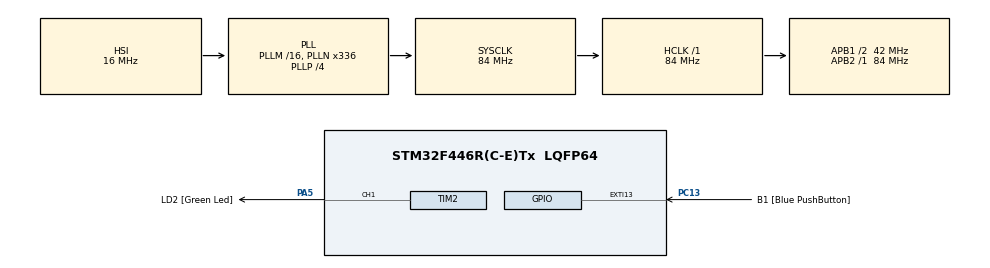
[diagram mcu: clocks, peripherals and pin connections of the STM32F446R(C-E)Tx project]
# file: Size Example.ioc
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Mcu.Family=STM32F4
Mcu.Name=STM32F446R(C-E)Tx
Mcu.Package=LQFP64
NVIC.PriorityGroup=NVIC_PRIORITYGROUP_0
PA13.GPIO_Label=TMS
PA13.Signal=SYS_JTMS-SWDIO
PA14.GPIO_Label=TCK
PA14.Signal=SYS_JTCK-SWCLK
PA2.GPIO_Label=USART_TX
PA2.Signal=USART2_TX
PA3.GPIO_Label=USART_RX
PA3.Signal=USART2_RX
PA5.GPIO_Label=LD2 [Green Led]
PA5.Signal=S_TIM2_CH1
PB3.GPIO_Label=SWO
PB3.Signal=SYS_JTDO-SWO
PC13.GPIO_Label=B1 [Blue PushButton]
PC13.GPIO_ModeDefaultEXTI=GPIO_MODE_IT_FALLING
PC13.Signal=GPXTI13
PC14-OSC32_IN.Signal=RCC_OSC32_IN
PC15-OSC32_OUT.Signal=RCC_OSC32_OUT
PH0-OSC_IN.Signal=RCC_OSC_IN
PH1-OSC_OUT.Signal=RCC_OSC_OUT
ProjectManager.HeapSize=0x200
ProjectManager.StackSize=0x400
ProjectManager.TargetToolchain=STM32CubeIDE
RCC.AHBFreq_Value=84000000
RCC.APB1CLKDivider=RCC_HCLK_DIV2
RCC.APB1Freq_Value=42000000
RCC.APB1TimFreq_Value=84000000
RCC.APB2Freq_Value=84000000
RCC.APB2TimFreq_Value=84000000
RCC.CortexFreq_Value=84000000
RCC.FLatency-AdvancedSettings=FLASH_LATENCY_2
RCC.HCLKFreq_Value=84000000
RCC.HSE_VALUE=8000000
RCC.HSI_VALUE=16000000
RCC.LSE_VALUE=32768
RCC.PLLN=336
RCC.PLLP=RCC_PLLP_DIV4
RCC.SYSCLKFreq_VALUE=84000000
RCC.SYSCLKSource=RCC_SYSCLKSOURCE_PLLCLK
RCC.USBFreq_Value=168000000
RCC.VCOOutputFreq_Value=336000000
SH.S_TIM2_CH1.0=TIM2_CH1,PWM Generation1 CH1
TIM2.Channel-PWM\ Generation1\ CH1=TIM_CHANNEL_1
TIM2.Period=2000000-1
TIM2.Prescaler=84-1
TIM2.Pulse=100000
board=NUCLEO-F446RE

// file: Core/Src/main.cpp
/* USER CODE BEGIN Header */
/**
  ******************************************************************************
  * @file           : main.c
  * @brief          : Main program body
  ******************************************************************************
  * @attention
  *
  * Copyright (c) 2026 STMicroelectronics.
  * All rights reserved.
  *
  * This software is licensed under terms that can be found in the LICENSE file
  * in the root directory of this software component.
  * If no LICENSE file comes with this software, it is provided AS-IS.
  *
  ******************************************************************************
  */
/* USER CODE END Header */
#include "main.h"

/* USER CODE BEGIN Includes */
#include <cstddef>
#include <cstdint>
#include "core_cm4.h"  // For CoreDebug and DWT register definitions

/* USER CODE END Includes */

TIM_HandleTypeDef htim2;

/* USER CODE BEGIN PV */
// Global variable to store CPU cycle count for run_scenario() (accessible via SWD)
volatile uint32_t g_cpu_cycles_used = 0;

// Global variable to store the number of bytes used in the serialization buffer. (accessible via SWD)
volatile uint32_t g_n_bytes_in_buffer = 0;
// Global variable to store the RAM taken by the scenario's message object. (accessible via SWD)
volatile uint32_t g_message_size_bytes = 0;
// Global variable to store the RAM the scenario took at its worst moment: the stack high-water
// mark below main() plus the heap it made newlib grow. (accessible via SWD)
volatile uint32_t g_peak_ram_bytes = 0;

/* USER CODE END PV */

void SystemClock_Config(void);
static void MX_GPIO_Init(void);
static void MX_TIM2_Init(void);
/* USER CODE BEGIN PFP */
// Function prototype for DWT cycle counter
void enable_dwt_cycle_counter();

/* USER CODE END PFP */

/* USER CODE BEGIN 0 */
// Forward declaration for scenario function
uint32_t run_scenario();

// The newlib heap, see sysmem.c. With an increment of zero it tells where the heap ends.
extern "C" void* _sbrk(ptrdiff_t increment);

// The free RAM between the heap and the stack is painted with this value before a scenario
// runs. Whatever the scenario touches loses the pattern, which tells how deep it went.
static constexpr uint32_t RAM_PAINT = 0xC5C5C5C5U;
// Bytes left unpainted right under the caller's stack pointer: room for the painter's own frame.
static constexpr uint32_t PAINT_MARGIN = 64U;

//! Paint the free RAM from the heap end up to the margin below the given stack pointer.
static void __attribute__((noinline)) paint_free_ram(const uint32_t stack_pointer)
{
  const uint32_t heap_end = reinterpret_cast<uint32_t>(_sbrk(0));
  uint32_t* word = reinterpret_cast<uint32_t*>((heap_end + 3U) & ~3U);
  uint32_t* const top = reinterpret_cast<uint32_t*>(stack_pointer - PAINT_MARGIN);
  while(word < top)
  {
    *word = RAM_PAINT;
    ++word;
  }
}

//! Peak RAM: how far below the stack pointer the pattern is gone, plus how far the heap grew.
static uint32_t __attribute__((noinline)) measure_peak_ram(const uint32_t stack_pointer,
                                                            const uint32_t heap_before)
{
  const uint32_t heap_after = reinterpret_cast<uint32_t>(_sbrk(0));
  const uint32_t* word = reinterpret_cast<const uint32_t*>((heap_after + 3U) & ~3U);
  const uint32_t* const top = reinterpret_cast<const uint32_t*>(stack_pointer - PAINT_MARGIN);
  while((word < top) && (RAM_PAINT == *word))
  {
    ++word;
  }
  const uint32_t stack_bytes = (word < top) ? (stack_pointer - reinterpret_cast<uint32_t>(word)) : 0U;
  return stack_bytes + (heap_after - heap_before);
}

/* USER CODE END 0 */

int main(void)
{

  /* MCU Configuration--------------------------------------------------------*/

  /* Reset of all peripherals, Initializes the Flash interface and the Systick. */
  HAL_Init();

  /* Configure the system clock */
  SystemClock_Config();

  /* Initialize all configured peripherals */
  MX_GPIO_Init();
  MX_TIM2_Init();
  /* USER CODE BEGIN 2 */
  // Blink LD2 from TIM2 in hardware while the board is in use. No code runs for it, so the
  // cycle count of the scenario is unaffected. The tool stops it with a reset after the read.
  HAL_TIM_PWM_Start(&htim2, TIM_CHANNEL_1);

  // Enable DWT cycle counter for CPU usage measurement
  enable_dwt_cycle_counter();

/* USER CODE END 2 */

  /* Infinite loop */
  while (1)
  {

    /* USER CODE BEGIN 3 */

    // No SysTick interrupt while measuring: its frames would show up in the stack high-water
    // mark and its cycles in the count.
    HAL_SuspendTick();
    const uint32_t stack_pointer = __get_MSP();
    const uint32_t heap_before = reinterpret_cast<uint32_t>(_sbrk(0));
    paint_free_ram(stack_pointer);

    // Reset cycle counter and capture start value
    DWT->CYCCNT = 0;

    // Run the selected scenario
    g_n_bytes_in_buffer = run_scenario();

    // Capture cycle count after scenario execution
    g_cpu_cycles_used = DWT->CYCCNT;

    g_peak_ram_bytes = measure_peak_ram(stack_pointer, heap_before);
    HAL_ResumeTick();

    // Infinite loop
    while(true)
    {
      asm("nop");
    }
  }
  /* USER CODE END 3 */
}

void SystemClock_Config(void)
{
  RCC_OscInitTypeDef RCC_OscInitStruct = {0};
  RCC_ClkInitTypeDef RCC_ClkInitStruct = {0};

  /** Configure the main internal regulator output voltage
  */
  __HAL_RCC_PWR_CLK_ENABLE();
  __HAL_PWR_VOLTAGESCALING_CONFIG(PWR_REGULATOR_VOLTAGE_SCALE3);

  /** Initializes the RCC Oscillators according to the specified parameters
  * in the RCC_OscInitTypeDef structure.
  */
  RCC_OscInitStruct.OscillatorType = RCC_OSCILLATORTYPE_HSI;
  RCC_OscInitStruct.HSIState = RCC_HSI_ON;
  RCC_OscInitStruct.HSICalibrationValue = RCC_HSICALIBRATION_DEFAULT;
  RCC_OscInitStruct.PLL.PLLState = RCC_PLL_ON;
  RCC_OscInitStruct.PLL.PLLSource = RCC_PLLSOURCE_HSI;
  RCC_OscInitStruct.PLL.PLLM = 16;
  RCC_OscInitStruct.PLL.PLLN = 336;
  RCC_OscInitStruct.PLL.PLLP = RCC_PLLP_DIV4;
  RCC_OscInitStruct.PLL.PLLQ = 2;
  RCC_OscInitStruct.PLL.PLLR = 2;
  if (HAL_RCC_OscConfig(&RCC_OscInitStruct) != HAL_OK)
  {
    Error_Handler();
  }

  /** Initializes the CPU, AHB and APB buses clocks
  */
  RCC_ClkInitStruct.ClockType = RCC_CLOCKTYPE_HCLK|RCC_CLOCKTYPE_SYSCLK
                              |RCC_CLOCKTYPE_PCLK1|RCC_CLOCKTYPE_PCLK2;
  RCC_ClkInitStruct.SYSCLKSource = RCC_SYSCLKSOURCE_PLLCLK;
  RCC_ClkInitStruct.AHBCLKDivider = RCC_SYSCLK_DIV1;
  RCC_ClkInitStruct.APB1CLKDivider = RCC_HCLK_DIV2;
  RCC_ClkInitStruct.APB2CLKDivider = RCC_HCLK_DIV1;

  if (HAL_RCC_ClockConfig(&RCC_ClkInitStruct, FLASH_LATENCY_2) != HAL_OK)
  {
    Error_Handler();
  }
}

static void MX_TIM2_Init(void)
{

  /* USER CODE BEGIN TIM2_Init 0 */
  // TIM2 runs from the APB1 timer clock, 84 MHz (APB1 at 42 MHz, doubled because the APB1
  // prescaler is 2). Prescaler 84 gives a 1 MHz count, period 2 s, LD2 on for 100 ms.
  /* USER CODE END TIM2_Init 0 */

  TIM_MasterConfigTypeDef sMasterConfig = {0};
  TIM_OC_InitTypeDef sConfigOC = {0};

  htim2.Instance = TIM2;
  htim2.Init.Prescaler = 84-1;
  htim2.Init.CounterMode = TIM_COUNTERMODE_UP;
  htim2.Init.Period = 2000000-1;
  htim2.Init.ClockDivision = TIM_CLOCKDIVISION_DIV1;
  htim2.Init.AutoReloadPreload = TIM_AUTORELOAD_PRELOAD_DISABLE;
  if (HAL_TIM_PWM_Init(&htim2) != HAL_OK)
  {
    Error_Handler();
  }
  sMasterConfig.MasterOutputTrigger = TIM_TRGO_RESET;
  sMasterConfig.MasterSlaveMode = TIM_MASTERSLAVEMODE_DISABLE;
  if (HAL_TIMEx_MasterConfigSynchronization(&htim2, &sMasterConfig) != HAL_OK)
  {
    Error_Handler();
  }
  sConfigOC.OCMode = TIM_OCMODE_PWM1;
  sConfigOC.Pulse = 100000;
  sConfigOC.OCPolarity = TIM_OCPOLARITY_HIGH;
  sConfigOC.OCFastMode = TIM_OCFAST_DISABLE;
  if (HAL_TIM_PWM_ConfigChannel(&htim2, &sConfigOC, TIM_CHANNEL_1) != HAL_OK)
  {
    Error_Handler();
  }
  HAL_TIM_MspPostInit(&htim2);

}

static void MX_GPIO_Init(void)
{
  GPIO_InitTypeDef GPIO_InitStruct = {0};

  /* GPIO Ports Clock Enable */
  __HAL_RCC_GPIOC_CLK_ENABLE();
  __HAL_RCC_GPIOH_CLK_ENABLE();
  __HAL_RCC_GPIOA_CLK_ENABLE();
  __HAL_RCC_GPIOB_CLK_ENABLE();

  /*Configure GPIO pin : B1_Pin */
  GPIO_InitStruct.Pin = B1_Pin;
  GPIO_InitStruct.Mode = GPIO_MODE_IT_FALLING;
  GPIO_InitStruct.Pull = GPIO_NOPULL;
  HAL_GPIO_Init(B1_GPIO_Port, &GPIO_InitStruct);

  /*Configure GPIO pins : USART_TX_Pin USART_RX_Pin */
  GPIO_InitStruct.Pin = USART_TX_Pin|USART_RX_Pin;
  GPIO_InitStruct.Mode = GPIO_MODE_AF_PP;
  GPIO_InitStruct.Pull = GPIO_NOPULL;
  GPIO_InitStruct.Speed = GPIO_SPEED_FREQ_VERY_HIGH;
  GPIO_InitStruct.Alternate = GPIO_AF7_USART2;
  HAL_GPIO_Init(GPIOA, &GPIO_InitStruct);

}

/* USER CODE BEGIN 4 */

/**
  * @brief Enable DWT cycle counter for CPU cycle measurement
  *        Must be called once during initialization
  * @retval None
  */
void enable_dwt_cycle_counter()
{
    // Enable trace and debug block (required for DWT)
    CoreDebug->DEMCR |= CoreDebug_DEMCR_TRCENA_Msk;
    // Reset the cycle counter
    DWT->CYCCNT = 0;
    // Enable the cycle counter
    DWT->CTRL |= DWT_CTRL_CYCCNTENA_Msk;
}

/* USER CODE END 4 */

void Error_Handler(void)
{
  __disable_irq();
  while (1)
  {
  }
}
